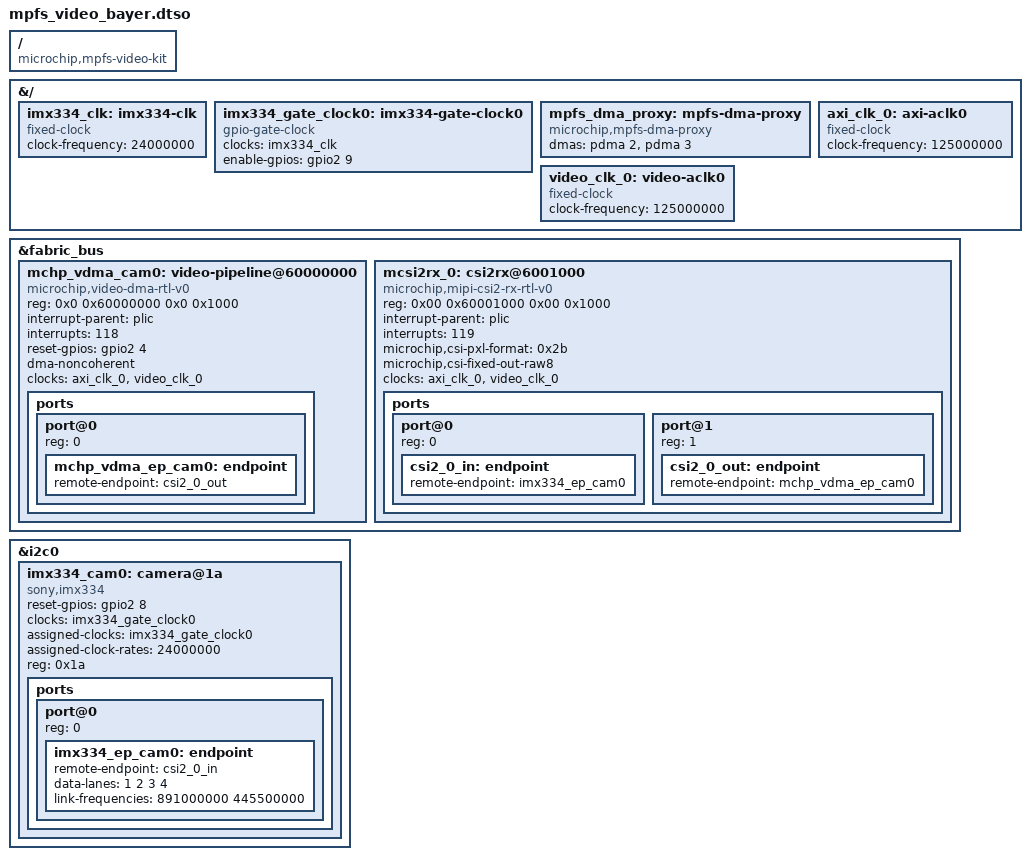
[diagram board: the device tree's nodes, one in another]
// SPDX-License-Identifier: (GPL-2.0+ OR MIT)
/*
 * Device Tree Overlay For Bayer Pipeline
 *
 * Copyright (C) 2022 Microchip Technology Inc. and its subsidiaries.
 * Author: shrava chippa <shravan.chippa@microchip.com>
 *
 */

/dts-v1/;
/plugin/;

#include <dt-bindings/gpio/gpio.h>

/ {
        compatible = "microchip,mpfs-video-kit","microchip,mpfs";
};

&{/} {
	imx334_clk: imx334-clk {
		compatible = "fixed-clock";
		#clock-cells = <0>;
		clock-frequency = <24000000>;
	};

	imx334_gate_clock0: imx334-gate-clock0 {
		compatible = "gpio-gate-clock";
		clocks = <&imx334_clk>;
		#clock-cells = <0>;
		enable-gpios = <&gpio2 9 GPIO_ACTIVE_HIGH>;
		status = "okay";
	};

	mpfs_dma_proxy: mpfs-dma-proxy {
		compatible = "microchip,mpfs-dma-proxy";
		dmas = <&pdma 2>, <&pdma 3>;
		dma-names = "dma-proxy0", "dma-proxy1";
	};

	axi_clk_0: axi-aclk0 {
		compatible = "fixed-clock";
		#clock-cells = <0>;
		clock-frequency = <125000000>;
	};

	video_clk_0: video-aclk0 {
		compatible = "fixed-clock";
		#clock-cells = <0>;
		clock-frequency = <125000000>;
	};
};

&fabric_bus {
	#address-cells = <2>;
	#size-cells = <2>;

	mchp_vdma_cam0: video-pipeline@60000000 {
		compatible = "microchip,video-dma-rtl-v0";
		reg = <0x0 0x60000000 0x0 0x1000>;
		interrupt-parent = <&plic>;
		interrupts = <118>;
		reset-gpios = <&gpio2 4 GPIO_ACTIVE_HIGH>;
		dma-noncoherent;
		clock-names = "axi", "video";
		clocks = <&axi_clk_0>, <&video_clk_0>;
		status = "okay";

		ports {
			#address-cells = <1>;
			#size-cells = <0>;

			port@0 {
				/* Sink port */
				reg = <0>;
				mchp_vdma_ep_cam0: endpoint {
					remote-endpoint = <&csi2_0_out>;
				};
			};

		};
	};

	mcsi2rx_0: csi2rx@6001000 {
		compatible = "microchip,mipi-csi2-rx-rtl-v0";
		reg = <0x00 0x60001000 0x00 0x1000>;
		interrupt-parent = <&plic>;
		interrupts = <119>;
		microchip,csi-pxl-format = <0x2b>;
		microchip,csi-fixed-out-raw8;
		clock-names = "axi", "video";
		clocks = <&axi_clk_0>, <&video_clk_0>;
		status = "okay";

		ports {
			#address-cells = <1>;
			#size-cells = <0>;

			port@0 {
				reg = <0>;
				csi2_0_in: endpoint {
					remote-endpoint = <&imx334_ep_cam0>;
				};
			};
			port@1 {
				reg = <1>;
				csi2_0_out: endpoint {
					remote-endpoint = <&mchp_vdma_ep_cam0>;
				};
			};
		};
	};
};

&i2c0 {
	#address-cells = <0x01>;
	#size-cells = <0x00>;

	imx334_cam0: camera@1a {
		compatible = "sony,imx334";
		reset-gpios = <&gpio2 8 GPIO_ACTIVE_HIGH>;
		clocks = <&imx334_gate_clock0>;
		assigned-clocks = <&imx334_gate_clock0>;
		assigned-clock-rates = <24000000>;
		reg = <0x1a>;
		status = "okay";

		ports {
			#address-cells = <1>;
			#size-cells = <0>;

			port@0 {
				reg = <0>;
				imx334_ep_cam0: endpoint {
					remote-endpoint = <&csi2_0_in>;
					data-lanes = <1 2 3 4>;
					link-frequencies = /bits/ 64 <891000000 445500000>;
				};
			};
		};
	};
};

